CM_ "carbagepilot.dbc starts here";

VERSION ""

NS_ :

BS_:

BU_:

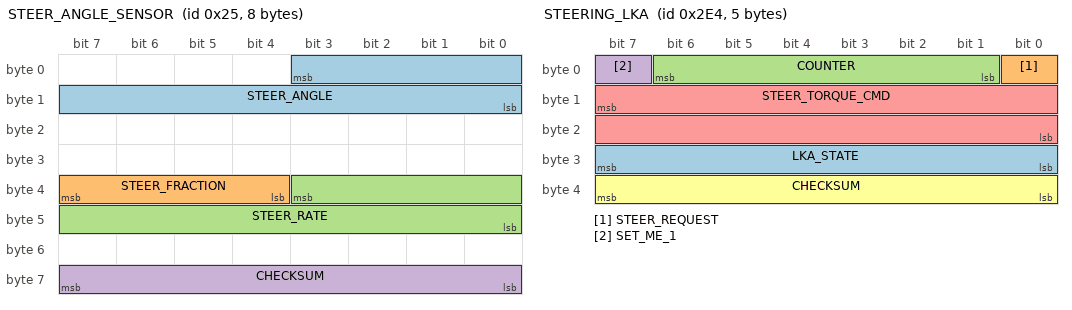
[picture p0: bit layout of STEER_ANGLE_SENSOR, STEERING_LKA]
BO_ 37 STEER_ANGLE_SENSOR: 8 XXX
 SG_ STEER_ANGLE : 3|12@0- (1.5,0) [-500|500] "deg" XXX
 SG_ STEER_FRACTION : 39|4@0- (0.1,0) [-0.7|0.7] "deg" XXX
 SG_ STEER_RATE : 35|12@0- (1,0) [-2000|2000] "deg/s" XXX
 SG_ CHECKSUM : 56|8@1+ (1,0) [0|255] "" XXX

BO_ 740 STEERING_LKA: 5 XXX
 SG_ LKA_STATE : 31|8@0+ (1,0) [0|255] "" XXX
 SG_ STEER_REQUEST : 0|1@0+ (1,0) [0|1] "" XXX
 SG_ COUNTER : 6|6@0+ (1,0) [0|63] "" XXX
 SG_ SET_ME_1 : 7|1@0+ (1,0) [0|1] "" XXX
 SG_ STEER_TORQUE_CMD : 15|16@0- (1,0) [0|65535] "" XXX
 SG_ CHECKSUM : 39|8@0+ (1,0) [0|255] "" XXX

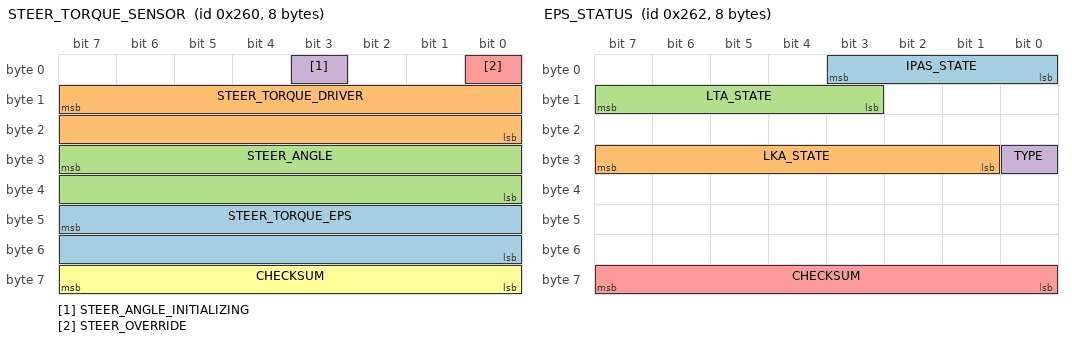
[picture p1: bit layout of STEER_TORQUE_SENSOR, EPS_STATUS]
BO_ 608 STEER_TORQUE_SENSOR: 8 XXX
 SG_ STEER_TORQUE_EPS : 47|16@0- (1,0) [-32768|32767] "" XXX
 SG_ STEER_TORQUE_DRIVER : 15|16@0- (1,0) [-32768|32767] "" XXX
 SG_ STEER_ANGLE : 31|16@0- (0.0573,0) [-500|500] "" XXX
 SG_ STEER_ANGLE_INITIALIZING : 3|1@0+ (1,0) [0|1] "" XXX
 SG_ STEER_OVERRIDE : 0|1@0+ (1,0) [0|1] "" XXX
 SG_ CHECKSUM : 63|8@0+ (1,0) [0|255] "" XXX

BO_ 610 EPS_STATUS: 8 EPS
 SG_ IPAS_STATE : 3|4@0+ (1,0) [0|15] "" XXX
 SG_ LKA_STATE : 31|7@0+ (1,0) [0|127] "" XXX
 SG_ LTA_STATE : 15|5@0+ (1,0) [0|31] "" XXX
 SG_ TYPE : 24|1@0+ (1,0) [0|1] "" XXX
 SG_ CHECKSUM : 63|8@0+ (1,0) [0|255] "" XXX

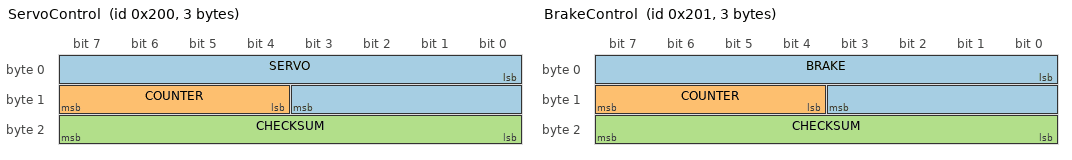
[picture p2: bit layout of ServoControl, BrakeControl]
BO_ 512 ServoControl: 3 ESP
  SG_ SERVO : 0|12@1+ (1,0) [0|100] "%" CBP
  SG_ COUNTER : 12|4@1+ (1,0) [0|15] "" CBP
  SG_ CHECKSUM : 16|8@1+ (1,0) [0|255] "" CBP

BO_ 513 BrakeControl: 3 ESP
  SG_ BRAKE : 0|12@1+ (0.015625,-5) [-5|47] "mm" CBP
  SG_ COUNTER : 12|4@1+ (1,0) [0|15] "" CBP
  SG_ CHECKSUM : 16|8@1+ (1,0) [0|255] "" CBP

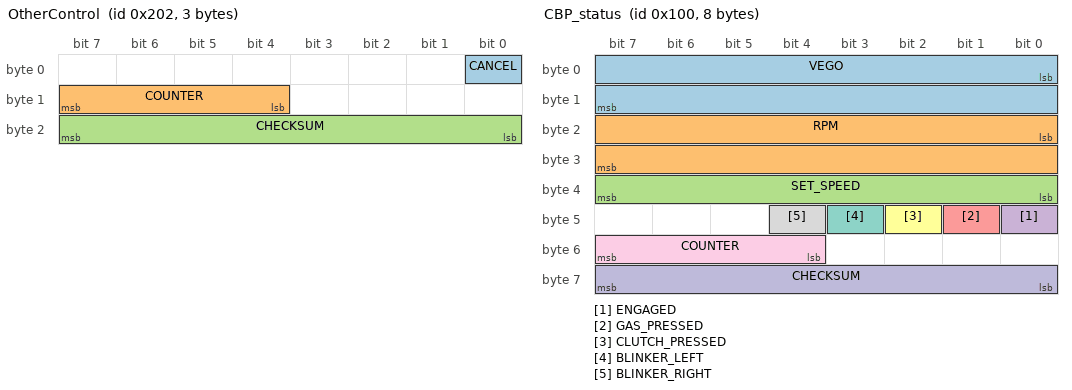
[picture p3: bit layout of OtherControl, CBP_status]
BO_ 514 OtherControl: 3 ESP
  SG_ CANCEL : 0|1@1+ (1,0) [0|1] "" CBP
  SG_ COUNTER : 12|4@1+ (1,0) [0|15] "" CBP
  SG_ CHECKSUM : 16|8@1+ (1,0) [0|255] "" CBP

BO_ 256 CBP_status: 8 CBP
  SG_ VEGO : 0|16@1+ (0.1,0) [0|65536] "km/h" OP
  SG_ RPM : 16|16@1+ (1,0) [0|65536] "rpm" OP
	SG_ SET_SPEED : 32|8@1+ (1,0) [0|255] "km/h" OP
	SG_ ENGAGED : 40|1@1+ (1,0) [0|1] "" OP
	SG_ GAS_PRESSED : 41|1@1+ (1,0) [0|1] "" OP
	SG_ CLUTCH_PRESSED : 42|1@1+ (1,0) [0|1] "" OP
	SG_ BLINKER_LEFT : 43|1@1+ (1,0) [0|1] "" OP
	SG_ BLINKER_RIGHT : 44|1@1+ (1,0) [0|1] "" OP
	SG_ COUNTER : 52|4@1+ (1,0) [0|15] "" OP
  SG_ CHECKSUM : 56|8@1+ (1,0) [0|255] "" OP

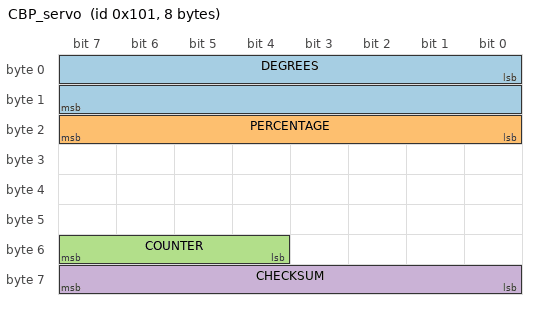
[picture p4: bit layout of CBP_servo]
BO_ 257 CBP_servo: 8 CBP
  SG_ DEGREES : 0|16@1+ (0.1,0) [0|65536] "deg" OP
  SG_ PERCENTAGE : 16|8@1+ (1,0) [0|100] "%" OP
	SG_ COUNTER : 52|4@1+ (1,0) [0|15] "" OP
  SG_ CHECKSUM : 56|8@1+ (1,0) [0|255] "" OP

BA_ "GenMsgCycleTime" BO_ 256 10;
BA_ "GenMsgSendType" BO_ 256 0;

VAL_ 610 IPAS_STATE 5 "override" 3 "enabled" 1 "disabled";
VAL_ 610 LKA_STATE 25 "temporary_fault" 17 "permanent_fault" 11 "lka_missing_unavailable2" 9 "temporary_fault2" 5 "active" 3 "lka_missing_unavailable" 1 "standby";
VAL_ 610 LTA_STATE 25 "temporary_fault" 9 "temporary_fault2" 5 "active" 3 "lta_missing_unavailable" 1 "standby";
